# MAX32550 register map
Vendor: Maxim Integrated; File version: 1.0
Registers are 32-bit, read-write, reset 0x0 unless marked. A register's access mark holds for its fields unless they carry their own. Offsets are from the block's base; [hi:lo] are bit positions; {n}, {i} and the like mark numbered series; 'fields as' and 'values as' point back to an identical list.

## GlobalControl — Registers controlling global functions
Base 0x40000000
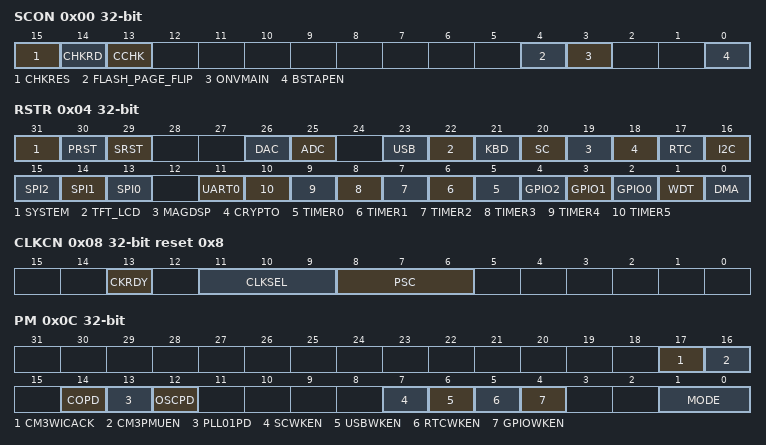
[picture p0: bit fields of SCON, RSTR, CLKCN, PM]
0x00 SCON (reset mask 0xFFFFFFFE) — System Control
  [15] CHKRES — ROM Checksum Result. This bit is only valid when CHKRD=1.
    0=pass; 1=fail
  [14] CHKRD — ROM Checksum Ready. This bit is self-cleared when a new checksum calculation is started (CCHK is set).
    0=busy (Result not ready); 1=ready (Operation complete and result ready)
  [13] CCHK — Compute ROM Checksum. This bit is self-cleared when calculation is completed. Once set, software clearing this bit is ignored and the bit will remain set until the operation is completed.
    0=complete (No operation/complete); 1=Start operation
  [4] FLASH_PAGE_FLIP — Flips the Flash bottom and top halves. (Depending on the total flash size, each half is either 256K or 512K). Initiating a flash page flip will cause a flush of both the data buffer on the DCODE bus and the internal instruction buffer.
    0=normal (Physical layout matches logical layout.); 1=swapped (Bottom half mapped to logical top half and vice versa.)
  [3] ONVMAIN — Battery supply source flag
    0=VBAT is selected to supply battery supply; 1=VMAIN is selected to supply battery supply
  [0] BSTAPEN — Boundary Scan TAP enable. When enabled, the JTAG port is connected to the Boundary Scan TAP. Otherwise, the port is connected to the ARM ICE function. This bit is reset by the POR. Reset value and access depend on the part number.
    0=disable; 1=enable
0x04 RSTR — Reset
  [all] fields
    on write: 1=reset (Starts reset operation) | on read: 0=Reset complete; 1=busy (Reset in progress)
  [31] SYSTEM — System Reset. Setting this bit to 1 resets the CPU core and all peripherals, including the watchdog timer.
  [30] PRST — Peripheral Reset. Setting this bit to 1 resets all peripherals. The CPU core, the watchdog timer, and all GPIO pins are unaffected by this reset.
  [29] SRST — Soft Reset. Setting this bit to 1 resets everything except the CPU and the watchdog timer.
  [26] DAC — Digital to Analog Reset
  [25] ADC — Analog to Digital Reset
  [23] USB — USB Reset. Setting this bit resets both USB blocks.
  [22] TFT_LCD — TFT/LCD Reset. Setting this bit to 1 resets both the TFT and mono LCD blocks.
  [21] KBD — Secure Keypad Reset
  [20] SC — Smart Card Reader Reset
  [19] MAGDSP — Magnetic Strip Reader Reset
  [18] CRYPTO — Cryptographic Reset. Setting this bit to 1 resets the AES block, the SHA block and the DES block.
  [17] RTC — Real Time Clock Reset
  [16] I2C — I2C Reset
  [15] SPI2 — SPI2 Reset. Setting this bit to 1 resets all SPI 2 blocks.
  [14] SPI1 — SPI1 Reset. Setting this bit to 1 resets all SPI 1 blocks.
  [13] SPI0 — SPI0 Reset. Setting this bit to 1 resets all SPI 0 blocks.
  [11] UART0 — UART0 Reset. Setting this bit to 1 resets all UART 0 blocks.
  [n+5] TIMER{n} (n=0..5) — Timer{n} Reset. Setting this bit to 1 resets Timer {n} blocks.
  [4] GPIO2 — GPIO2 Reset. Setting this bit to 1 resets GPIO2 pins to their default states.
  [3] GPIO1 — GPIO1 Reset. Setting this bit to 1 resets GPIO1 pins to their default states.
  [2] GPIO0 — GPIO0 Reset. Setting this bit to 1 resets GPIO0 pins to their default states.
  [1] WDT — Watchdog Timer Reset
  [0] DMA — DMA Reset
0x08 CLKCN reset 0x8 — Clock Control
  [13] CKRDY ro — Clock Ready. This read only bit reflects whether the currently selected system clock source is running.
    values as SCON.CHKRD
  [11:9] CLKSEL — Clock Source Select. This 3 bit field selects the source for the system clock.
    0=Crypto oscillator is used for the system clock; 1=pllOutput (The PLL output is used for the system clock.); 2=HFXIN is used for the system clock; 3=nanoRing (The nano-ring output is used for the system clock.)
  [8:6] PSC — Prescaler Select. This 3 bit field sets the system operating frequency by controlling the prescaler that divides the output of the PLL0.
    0=div1 (Divide by 1); 1=div2 (Divide by 2); 2=div4 (Divide by 4); 3=div8 (Divide by 8); 4=div16 (Divide by 16); 5=div32 (Divide by 32); 6=div64 (Divide by 64); 7=div128 (Divide by 128)
0x0C PM — Power Management
  [17] CM3WICACK ro — CM3 WIC Acknowledge. This status bit reflects the state of the CM3 WIC acknowledge to PMU request.
  [16] CM3PMUEN — CM3 Power Management Enable. Setting this bit will allow the CM3_DEEPSLEEP or CM3_SLEEPING state to put the device into STANDBY mode.
    0=disable; 1=enable
  [14] COPD — Crypto Oscillator Power Down. This bit selects crypto oscillator power state in STANDBY mode.
    0=active (In active mode); 1=standBy (In standby mode)
  [13] PLL01PD — PLL0/1 Power Down. This bit selects PLL power state in STANDBY mode.
    0=active (In active mode); 1=standBy (In standby mode)
  [12] OSCPD — External Oscillator Power Down. Setting this bit prior to entering the STANDBY mode, powers down the External Oscillator circuit.
    0=disable; 1=enable
  [7] SCWKEN — Smart Card Wake Up Enable. This bit enables Smart Card activity as a wakeup source.
    0=disable; 1=enable
  [6] USBWKEN — USB Wake Up Enable. This bit enables USB activity as wakeup source.
    0=disable; 1=enable
  [5] RTCWKEN — RTC Alarm Wake Up Enable. This bit enables RTC alarm as wakeup source. If enabled, the desired RTC alarm must be configured via the RTC control registers.
    0=disable; 1=enable
  [4] GPIOWKEN — GPIO Wake Up Enable. This bit enables all GPIO pins as potential wakeup sources. Any GPIO configured for wakeup is capable of causing an exit from IDLE or STANDBY modes when this bit is set.
    0=disable; 1=enable
  [1:0] MODE — Operating Mode. This two bit field selects the current operating mode for the device. Note that code execution only occurs during ACTIVE mode.
    0=active; 1=idle; 2=standby; 3=shutdown
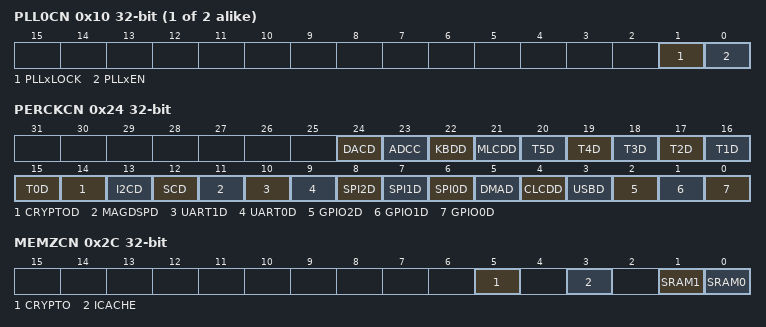
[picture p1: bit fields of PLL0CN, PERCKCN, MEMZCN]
{0x10+4i} PLL{i}CN (i=0..1) — PLL Control
  [1] PLLxLOCK ro — PLL Lock. This bit is set by hardware when the PLL is locked to the input clock. It is cleared when the PLL is disabled, lock is not yet achieved or when the lock is lost.
    on read: 0=unlocked; 1=locked
  [0] PLLxEN — PLL Enable. This bit enables system PLL for clock multiplication.
    0=disable; 1=enable
0x18 PCKDIV reset 0x3 — Peripheral Clock Divider
  [2:0] PCF — These bits determine the clock frequency for the UART, I2C and Key Pad peripherals. These peripherals have an adaptive clock generator that dynamically adjusts the peripheral frequency based on the main system bus frequency. These bits are dynamically updated when the PLL0 is selected as the system clock source and are set by hardware. These bits determine the clock frequency for the UART, I2C and Key Pad peripherals. These peripherals have an adaptive clock generator that dynamically adjusts the peripheral frequency based on the main system bus frequency. These bits are dynamically updated when the PLL0 is selected as the system clock source and are set by hardware.
0x24 PERCKCN — Peripheral Clock Disable
  [all] fields
    0=enable; 1=disable
  [24] DACD — DAC Disable
  [23] ADCC — ADC Disable
  [22] KBDD — Keypad Disable
  [21] MLCDD — Mono LCD Disable
  [n+15] T{n}D (n=0..5) — Timer {n} Disable
  [14] CRYPTOD — Crypto Disable
  [13] I2CD — I2C Disable
  [12] SCD — Smart Card Disable
  [11] MAGDSPD — Magnetic Stripe DSP Disable
  [10] UART1D — UART 1 Disable
  [9] UART0D — UART 0 Disable
  [8] SPI2D — SPI 2 Disable
  [7] SPI1D — SPI 1 Disable
  [6] SPI0D — SPI 0 Disable
  [5] DMAD — DMA Disable
  [4] CLCDD — Color LCD Controller Disable
  [3] USBD — USB Disable
  [2] GPIO2D — GPIO2 Disable
  [1] GPIO1D — GPIO1 Disable
  [0] GPIO0D — GPIO0 Disable
0x2C MEMZCN — Memory Zeroize Control
  [all] fields
    0=nop (No operation/complete); 1=Start operation
  [5] CRYPTO — Crypto (MAA) Memory
  [3] ICACHE — Instruction Cache
  [1] SRAM1 — System RAM Block 1
  [0] SRAM0 — System RAM Block 0
0x34 SCCK reset 0x14 — Smart Card Clock Control
  [5:0] SC0FRQ — Smart Card 0 Clock Frequency. These bits define Smart Card 0 clock frequency. f_SC0 = f_PLL1 / SC0FRQ
